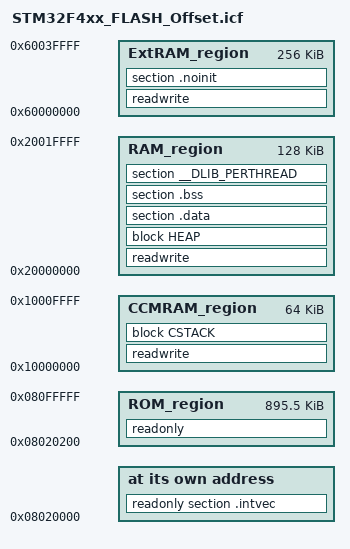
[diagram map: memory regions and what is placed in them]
/*###ICF### Section handled by ICF editor, don't touch! ****/
/*-Editor annotation file-*/
/* IcfEditorFile="$TOOLKIT_DIR$\config\ide\IcfEditor\cortex_v1_0.xml" */
/*-Specials-*/
define symbol __ICFEDIT_intvec_start__ = 0x08020000;
/*-Memory Regions-*/
define symbol __ICFEDIT_region_ROM_start__    = 0x08020200;
define symbol __ICFEDIT_region_ROM_end__      = 0x080FFFFF;
define symbol __ICFEDIT_region_RAM_start__    = 0x20000000;
define symbol __ICFEDIT_region_RAM_end__      = 0x2001FFFF;
define symbol __ICFEDIT_region_CCMRAM_start__ = 0x10000000;
define symbol __ICFEDIT_region_CCMRAM_end__   = 0x1000FFFF;
define symbol __ICFEDIT_region_ExtRAM_start__ = 0x60000000;
define symbol __ICFEDIT_region_ExtRAM_end__   = 0x6003FFFF;

/*-Sizes-*/
define symbol __ICFEDIT_size_cstack__ = 0x5000;
define symbol __ICFEDIT_size_heap__   = 0x100;
/**** End of ICF editor section. ###ICF###*/


define memory mem with size = 4G;
define region ROM_region      = mem:[from __ICFEDIT_region_ROM_start__   to __ICFEDIT_region_ROM_end__];
define region RAM_region      = mem:[from __ICFEDIT_region_RAM_start__   to __ICFEDIT_region_RAM_end__];
define region CCMRAM_region   = mem:[from __ICFEDIT_region_CCMRAM_start__   to __ICFEDIT_region_CCMRAM_end__];
define region ExtRAM_region   = mem:[from __ICFEDIT_region_ExtRAM_start__   to __ICFEDIT_region_ExtRAM_end__];

define block CSTACK    with alignment = 8, size = __ICFEDIT_size_cstack__   { };
define block HEAP      with alignment = 8, size = __ICFEDIT_size_heap__     { };
/* define block SRAM      with alignment = 4  { section .sram }; */

initialize by copy { readwrite };
do not initialize  { section .noinit };

place at address mem:__ICFEDIT_intvec_start__ { readonly section .intvec };

place in ROM_region   { readonly };
place in CCMRAM_region   { readwrite,
                        block CSTACK};
place in RAM_region   { readwrite,
                        block HEAP, section .data, section .bss, section __DLIB_PERTHREAD};
place in ExtRAM_region{ readwrite, section .noinit};                        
